# PIC32MX270F256D register map
Vendor: Microchip
Registers are 32-bit, read-write, reset 0x0 unless marked. A register's access mark holds for its fields unless they carry their own. Addresses are absolute, and some are shared; only a register's first bit layout is shown; [hi:lo] are bit positions; {n}, {i} and the like mark numbered series.

## DMAC2
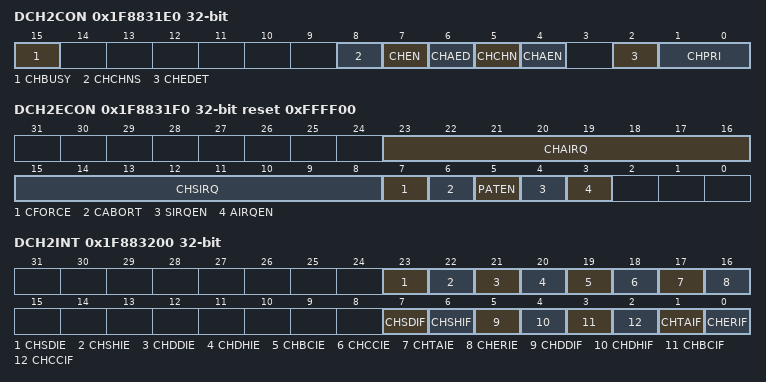
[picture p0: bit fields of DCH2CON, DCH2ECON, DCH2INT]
0x1F8831E0 DCH2CON reset not defined — (power-on value ----------------x------00000-000)
  [15] CHBUSY, [8] CHCHNS, [7] CHEN, [6] CHAED, [5] CHCHN, [4] CHAEN, [2] CHEDET ro, [1:0] CHPRI
0x1F8831F0 DCH2ECON reset 0xFFFF00
  [23:16] CHAIRQ
  [15:8] CHSIRQ
  [7] CFORCE — (can only be set)
  [6] CABORT — (can only be set)
  [5] PATEN
  [4] SIRQEN
  [3] AIRQEN
0x1F883200 DCH2INT
  [23] CHSDIE, [22] CHSHIE, [21] CHDDIE, [20] CHDHIE, [19] CHBCIE, [18] CHCCIE, [17] CHTAIE, [16] CHERIE, [7] CHSDIF, [6] CHSHIF, [5] CHDDIF, [4] CHDHIF, [3] CHBCIF, [2] CHCCIF, [1] CHTAIF, [0] CHERIF
0x1F883210 DCH2SSA reset not defined — (power-on value xxxxxxxxxxxxxxxxxxxxxxxxxxxxxxxx)
0x1F883220 DCH2DSA reset not defined — (power-on value xxxxxxxxxxxxxxxxxxxxxxxxxxxxxxxx)
0x1F883230 DCH2SSIZ reset not defined — (power-on value ----------------xxxxxxxxxxxxxxxx)
  [15:0] CHSSIZ
0x1F883240 DCH2DSIZ reset not defined — (power-on value ----------------xxxxxxxxxxxxxxxx)
  [15:0] CHDSIZ
0x1F883250 DCH2SPTR reset not defined — (power-on value ----------------xxxxxxxxxxxxxxxx)
  [15:0] CHSPTR
0x1F883260 DCH2DPTR ro
  [15:0] CHDPTR
0x1F883270 DCH2CSIZ reset not defined — (power-on value ----------------xxxxxxxxxxxxxxxx)
  [15:0] CHCSIZ
0x1F883280 DCH2CPTR reset not defined — (power-on value ----------------xxxxxxxxxxxxxxxx)
  [15:0] CHCPTR
0x1F883290 DCH2DAT reset not defined — (power-on value ------------------------xxxxxxxx)
  [7:0] DCHPDAT

## DMAC3
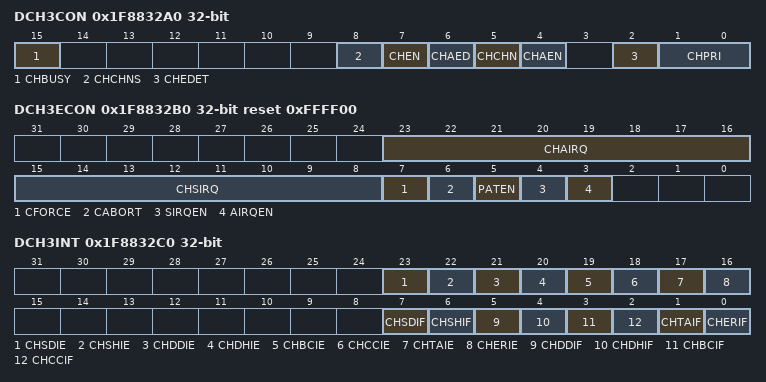
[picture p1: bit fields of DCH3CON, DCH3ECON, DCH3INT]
0x1F8832A0 DCH3CON reset not defined — (power-on value ----------------x------00000-000)
  [15] CHBUSY, [8] CHCHNS, [7] CHEN, [6] CHAED, [5] CHCHN, [4] CHAEN, [2] CHEDET ro, [1:0] CHPRI
0x1F8832B0 DCH3ECON reset 0xFFFF00
  [23:16] CHAIRQ
  [15:8] CHSIRQ
  [7] CFORCE — (can only be set)
  [6] CABORT — (can only be set)
  [5] PATEN
  [4] SIRQEN
  [3] AIRQEN
0x1F8832C0 DCH3INT
  [23] CHSDIE, [22] CHSHIE, [21] CHDDIE, [20] CHDHIE, [19] CHBCIE, [18] CHCCIE, [17] CHTAIE, [16] CHERIE, [7] CHSDIF, [6] CHSHIF, [5] CHDDIF, [4] CHDHIF, [3] CHBCIF, [2] CHCCIF, [1] CHTAIF, [0] CHERIF
0x1F8832D0 DCH3SSA reset not defined — (power-on value xxxxxxxxxxxxxxxxxxxxxxxxxxxxxxxx)
0x1F8832E0 DCH3DSA reset not defined — (power-on value xxxxxxxxxxxxxxxxxxxxxxxxxxxxxxxx)
0x1F8832F0 DCH3SSIZ reset not defined — (power-on value ----------------xxxxxxxxxxxxxxxx)
  [15:0] CHSSIZ
0x1F883300 DCH3DSIZ reset not defined — (power-on value ----------------xxxxxxxxxxxxxxxx)
  [15:0] CHDSIZ
0x1F883310 DCH3SPTR reset not defined — (power-on value ----------------xxxxxxxxxxxxxxxx)
  [15:0] CHSPTR
0x1F883320 DCH3DPTR ro
  [15:0] CHDPTR
0x1F883330 DCH3CSIZ reset not defined — (power-on value ----------------xxxxxxxxxxxxxxxx)
  [15:0] CHCSIZ
0x1F883340 DCH3CPTR reset not defined — (power-on value ----------------xxxxxxxxxxxxxxxx)
  [15:0] CHCPTR
0x1F883350 DCH3DAT reset not defined — (power-on value ------------------------xxxxxxxx)
  [7:0] DCHPDAT

## USB
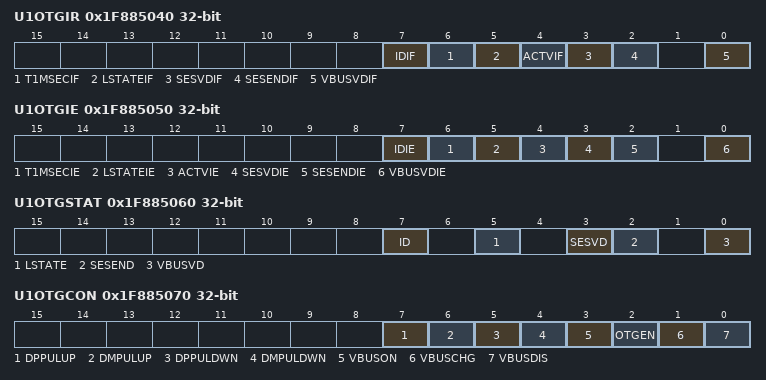
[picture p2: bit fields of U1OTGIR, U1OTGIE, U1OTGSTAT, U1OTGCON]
0x1F885040 U1OTGIR
  [7] IDIF, [6] T1MSECIF, [5] LSTATEIF, [4] ACTVIF, [3] SESVDIF, [2] SESENDIF, [0] VBUSVDIF
0x1F885050 U1OTGIE
  [7] IDIE, [6] T1MSECIE, [5] LSTATEIE, [4] ACTVIE, [3] SESVDIE, [2] SESENDIE, [0] VBUSVDIE
0x1F885060 U1OTGSTAT
  [7] ID, [5] LSTATE, [3] SESVD, [2] SESEND, [0] VBUSVD
0x1F885070 U1OTGCON
  [7] DPPULUP, [6] DMPULUP, [5] DPPULDWN, [4] DMPULDWN, [3] VBUSON, [2] OTGEN, [1] VBUSCHG, [0] VBUSDIS
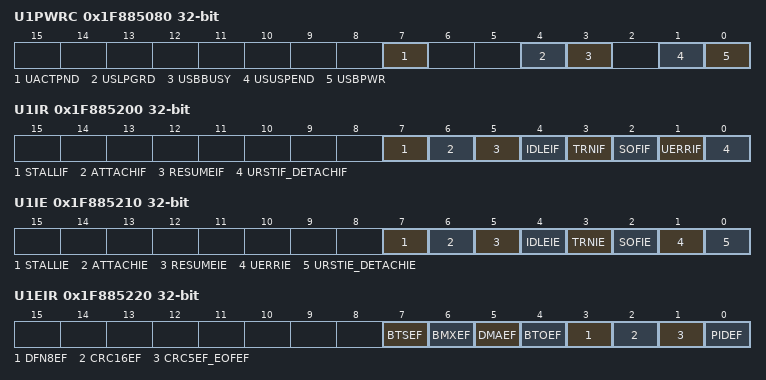
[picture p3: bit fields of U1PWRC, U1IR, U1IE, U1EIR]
0x1F885080 U1PWRC reset not defined — (power-on value ------------------------0--0x-00)
  [7] UACTPND ro, [4] USLPGRD, [3] USBBUSY, [1] USUSPEND, [0] USBPWR
0x1F885200 U1IR
  [7] STALLIF, [6] ATTACHIF, [5] RESUMEIF, [4] IDLEIF, [3] TRNIF, [2] SOFIF, [1] UERRIF, [0] URSTIF_DETACHIF
0x1F885210 U1IE
  [7] STALLIE, [6] ATTACHIE, [5] RESUMEIE, [4] IDLEIE, [3] TRNIE, [2] SOFIE, [1] UERRIE, [0] URSTIE_DETACHIE
0x1F885220 U1EIR
  [7] BTSEF, [6] BMXEF, [5] DMAEF, [4] BTOEF, [3] DFN8EF, [2] CRC16EF, [1] CRC5EF_EOFEF, [0] PIDEF
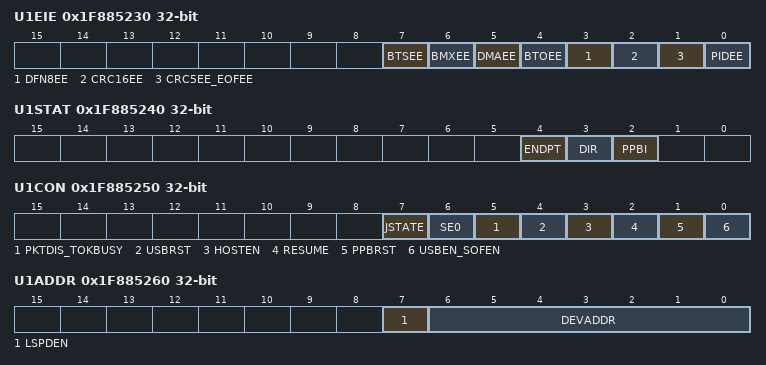
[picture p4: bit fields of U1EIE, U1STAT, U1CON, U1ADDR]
0x1F885230 U1EIE reset not defined — (power-on value ------------------------0000000x)
  [7] BTSEE, [6] BMXEE, [5] DMAEE, [4] BTOEE, [3] DFN8EE, [2] CRC16EE, [1] CRC5EE_EOFEE, [0] PIDEE
0x1F885240 U1STAT ro reset not defined
  [4] ENDPT, [3] DIR, [2] PPBI
0x1F885250 U1CON
  [7] JSTATE, [6] SE0, [5] PKTDIS_TOKBUSY, [4] USBRST, [3] HOSTEN, [2] RESUME, [1] PPBRST, [0] USBEN_SOFEN
0x1F885260 U1ADDR
  [7] LSPDEN, [6:0] DEVADDR
0x1F885270 U1BDTP1
  [7:1] BDTPTRL
0x1F885280 U1FRML ro reset not defined
  [7:0] FRML
0x1F885290 U1FRMH ro reset not defined
  [2:0] FRMH
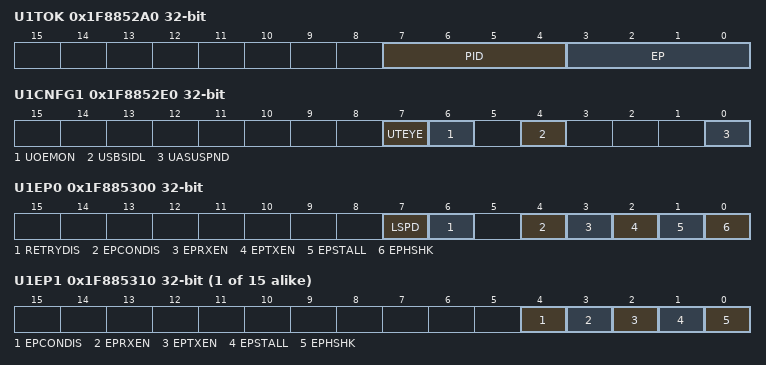
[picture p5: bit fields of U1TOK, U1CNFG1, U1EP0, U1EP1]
0x1F8852A0 U1TOK
  [7:4] PID, [3:0] EP
0x1F8852B0 U1SOF
  [7:0] CNT
0x1F8852C0 U1BDTP2
  [7:0] BDTPTRH
0x1F8852D0 U1BDTP3
  [7:0] BDTPTRU
0x1F8852E0 U1CNFG1 reset not defined — (power-on value ------------------------xxxx-00x)
  [7] UTEYE, [6] UOEMON, [4] USBSIDL, [0] UASUSPND
0x1F885300 U1EP0
  [7] LSPD, [6] RETRYDIS, [4] EPCONDIS, [3] EPRXEN, [2] EPTXEN, [1] EPSTALL, [0] EPHSHK
{0x1F885300+0x10*i} U1EP{i} (i=1..15)
  [4] EPCONDIS, [3] EPRXEN, [2] EPTXEN, [1] EPSTALL, [0] EPHSHK

## TRAA_Ports
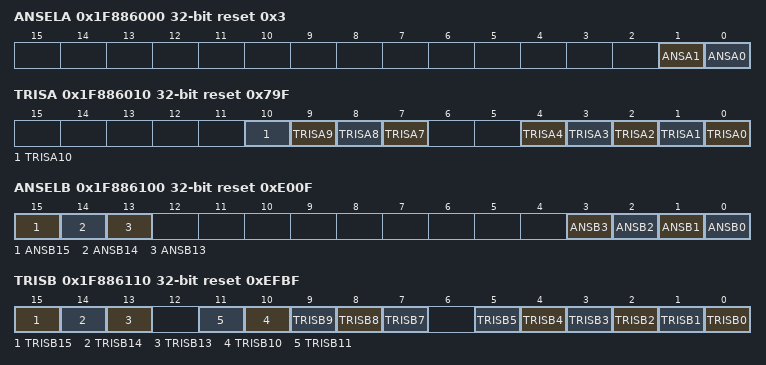
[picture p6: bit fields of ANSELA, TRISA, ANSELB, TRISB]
0x1F886000 ANSELA reset 0x3
  [1] ANSA1, [0] ANSA0
0x1F886010 TRISA reset 0x79F
  [n] TRISA{n} (n=7..10), [n] TRISA{n} (n=0..4)
0x1F886100 ANSELB reset 0xE00F
  [15] ANSB15, [14] ANSB14, [13] ANSB13, [n] ANSB{n} (n=0..3)
0x1F886110 TRISB reset 0xEFBF
  [15] TRISB15, [14] TRISB14, [13] TRISB13, [n] TRISB{n} (n=7..11), [n] TRISB{n} (n=0..5)
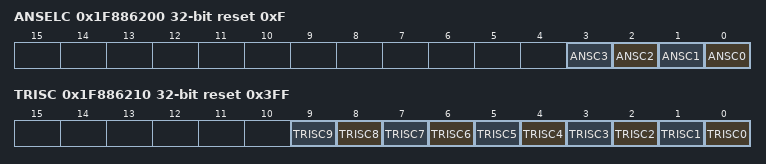
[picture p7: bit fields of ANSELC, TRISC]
0x1F886200 ANSELC reset 0xF
  [n] ANSC{n} (n=0..3)
0x1F886210 TRISC reset 0x3FF
  [n] TRISC{n} (n=0..9)

## PORTA
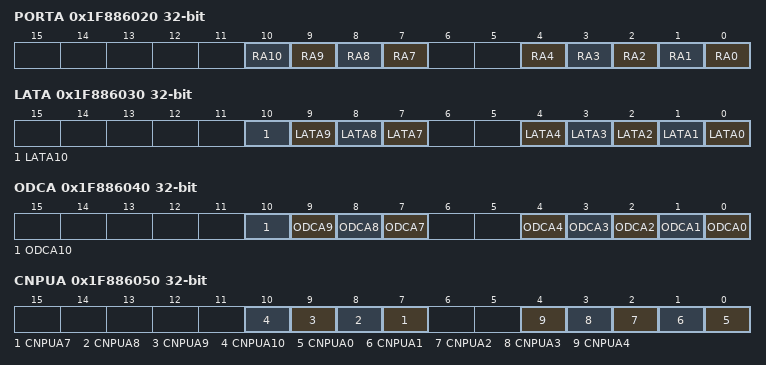
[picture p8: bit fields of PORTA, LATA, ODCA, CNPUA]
0x1F886020 PORTA reset not defined — (power-on value ---------------------xxxx--xxxxx)
  [n] RA{n} (n=7..10), [n] RA{n} (n=0..4)
0x1F886030 LATA reset not defined — (power-on value ---------------------xxxx--xxxxx)
  [n] LATA{n} (n=7..10), [n] LATA{n} (n=0..4)
0x1F886040 ODCA
  [n] ODCA{n} (n=7..10), [n] ODCA{n} (n=0..4)
0x1F886050 CNPUA reset not defined — (power-on value ---------------------xxxx--xxxxx)
  [n] CNPUA{n} (n=7..10), [n] CNPUA{n} (n=0..4)
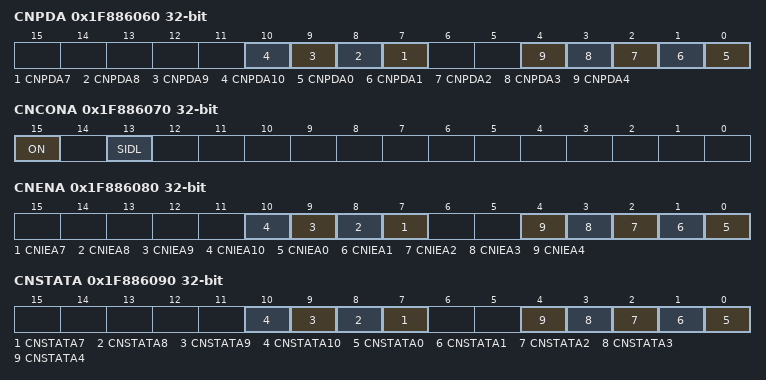
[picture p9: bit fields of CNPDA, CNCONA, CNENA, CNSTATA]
0x1F886060 CNPDA reset not defined — (power-on value ---------------------xxxx--xxxxx)
  [n] CNPDA{n} (n=7..10), [n] CNPDA{n} (n=0..4)
0x1F886070 CNCONA
  [15] ON, [13] SIDL
0x1F886080 CNENA reset not defined — (power-on value 0000000000-----------xxxx--xxxxx)
  [n] CNIEA{n} (n=7..10), [n] CNIEA{n} (n=0..4)
0x1F886090 CNSTATA reset not defined — (power-on value ---------------------xxxx--xxxxx)
  [n] CNSTATA{n} (n=7..10), [n] CNSTATA{n} (n=0..4)

## PORTB
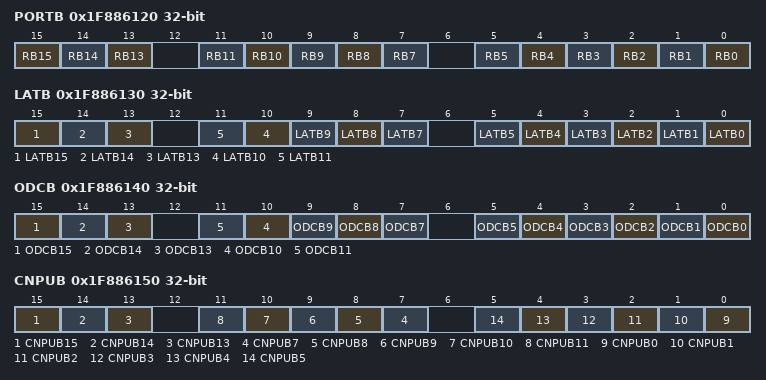
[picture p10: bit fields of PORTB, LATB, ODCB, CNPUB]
0x1F886120 PORTB reset not defined — (power-on value ----------------xxx-xxxxx-xxxxxx)
  [15] RB15, [14] RB14, [13] RB13, [n] RB{n} (n=7..11), [n] RB{n} (n=0..5)
0x1F886130 LATB reset not defined — (power-on value ----------------xxx-xxxxx-xxxxxx)
  [15] LATB15, [14] LATB14, [13] LATB13, [n] LATB{n} (n=7..11), [n] LATB{n} (n=0..5)
0x1F886140 ODCB
  [15] ODCB15, [14] ODCB14, [13] ODCB13, [n] ODCB{n} (n=7..11), [n] ODCB{n} (n=0..5)
0x1F886150 CNPUB reset not defined — (power-on value ----------------xxx-xxxxx-xxxxxx)
  [15] CNPUB15, [14] CNPUB14, [13] CNPUB13, [n] CNPUB{n} (n=7..11), [n] CNPUB{n} (n=0..5)
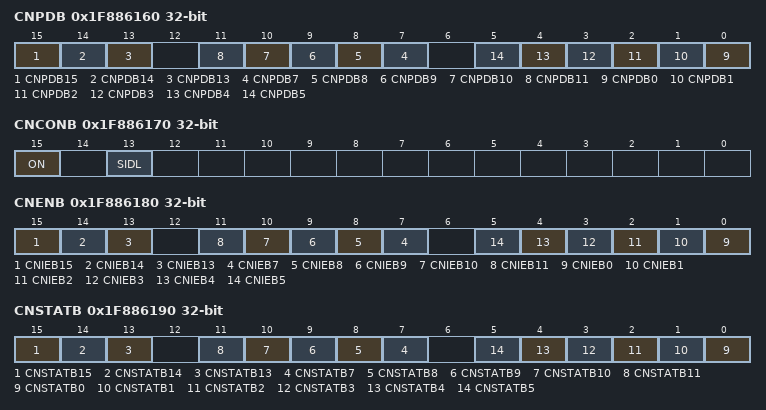
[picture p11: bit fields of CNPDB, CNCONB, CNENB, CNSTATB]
0x1F886160 CNPDB reset not defined — (power-on value ----------------xxx-xxxxx-xxxxxx)
  [15] CNPDB15, [14] CNPDB14, [13] CNPDB13, [n] CNPDB{n} (n=7..11), [n] CNPDB{n} (n=0..5)
0x1F886170 CNCONB
  [15] ON, [13] SIDL
0x1F886180 CNENB reset not defined — (power-on value 0000000000------xxx-xxxxx-xxxxxx)
  [15] CNIEB15, [14] CNIEB14, [13] CNIEB13, [n] CNIEB{n} (n=7..11), [n] CNIEB{n} (n=0..5)
0x1F886190 CNSTATB reset not defined — (power-on value ----------------xxx-xxxxx-xxxxxx)
  [15] CNSTATB15, [14] CNSTATB14, [13] CNSTATB13, [n] CNSTATB{n} (n=7..11), [n] CNSTATB{n} (n=0..5)

## PORTC
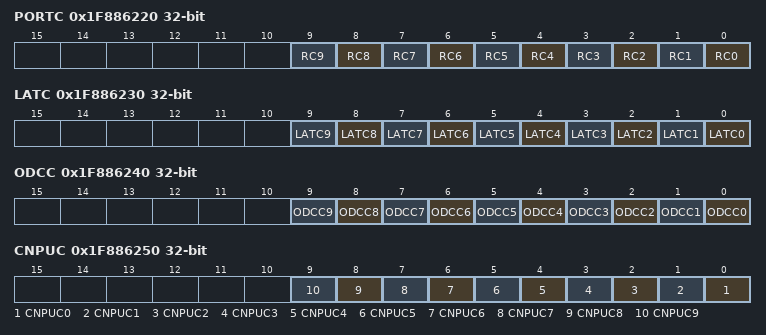
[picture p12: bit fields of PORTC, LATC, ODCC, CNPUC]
0x1F886220 PORTC reset not defined — (power-on value ----------------------xxxxxxxxxx)
  [n] RC{n} (n=0..9)
0x1F886230 LATC reset not defined — (power-on value ----------------------xxxxxxxxxx)
  [n] LATC{n} (n=0..9)
0x1F886240 ODCC
  [n] ODCC{n} (n=0..9)
0x1F886250 CNPUC reset not defined — (power-on value ----------------------xxxxxxxxxx)
  [n] CNPUC{n} (n=0..9)
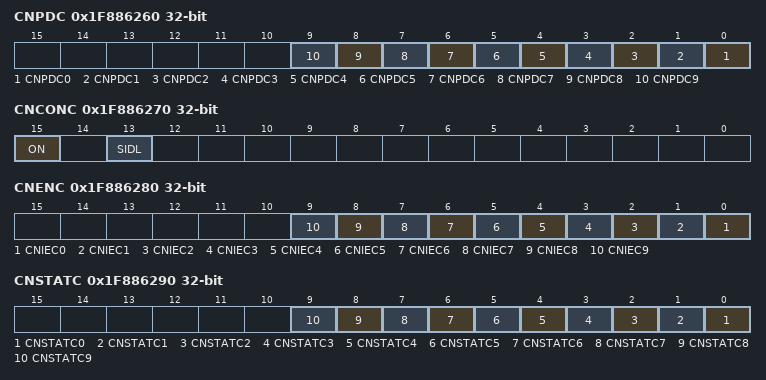
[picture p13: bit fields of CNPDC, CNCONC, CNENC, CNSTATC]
0x1F886260 CNPDC reset not defined — (power-on value ----------------------xxxxxxxxxx)
  [n] CNPDC{n} (n=0..9)
0x1F886270 CNCONC
  [15] ON, [13] SIDL
0x1F886280 CNENC reset not defined — (power-on value 0000000000------------xxxxxxxxxx)
  [n] CNIEC{n} (n=0..9)
0x1F886290 CNSTATC reset not defined — (power-on value ----------------------xxxxxxxxxx)
  [n] CNSTATC{n} (n=0..9)
